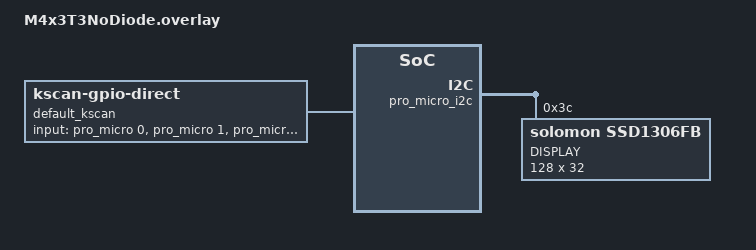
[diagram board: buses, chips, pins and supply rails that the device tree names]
#include <dt-bindings/zmk/matrix_transform.h>

/ {
	chosen {
		zmk,kscan = &default_kscan;
	};


	default_kscan: kscan {
		compatible = "zmk,kscan-gpio-direct";
		label = "default_kscan";

		diode-direction = "col2row";
		input-gpios
            = <&pro_micro 0 (GPIO_ACTIVE_HIGH | GPIO_PULL_DOWN)>
			, <&pro_micro 1 (GPIO_ACTIVE_HIGH | GPIO_PULL_DOWN)>
			, <&pro_micro 2 (GPIO_ACTIVE_HIGH | GPIO_PULL_DOWN)>
			, <&pro_micro 3 (GPIO_ACTIVE_HIGH | GPIO_PULL_DOWN)>
			, <&pro_micro 4 (GPIO_ACTIVE_HIGH | GPIO_PULL_DOWN)>
            , <&pro_micro 5 (GPIO_ACTIVE_HIGH | GPIO_PULL_DOWN)>
			, <&pro_micro 6 (GPIO_ACTIVE_HIGH | GPIO_PULL_DOWN)>
			, <&pro_micro 7 (GPIO_ACTIVE_HIGH | GPIO_PULL_DOWN)>
			, <&pro_micro 8 (GPIO_ACTIVE_HIGH | GPIO_PULL_DOWN)>
			, <&pro_micro 9 (GPIO_ACTIVE_HIGH | GPIO_PULL_DOWN)>
            , <&pro_micro 10 (GPIO_ACTIVE_HIGH | GPIO_PULL_DOWN)>
			, <&pro_micro 11 (GPIO_ACTIVE_HIGH | GPIO_PULL_DOWN)>
            , <&pro_micro 12 (GPIO_ACTIVE_HIGH | GPIO_PULL_DOWN)>
			, <&pro_micro 13 (GPIO_ACTIVE_HIGH | GPIO_PULL_DOWN)>
            , <&pro_micro 14 (GPIO_ACTIVE_HIGH | GPIO_PULL_DOWN)>
			;

	};


};

&pro_micro_i2c {
	status = "okay";

	oled: ssd1306@3c {
		compatible = "solomon,ssd1306fb";
		reg = <0x3c>;
		label = "DISPLAY";
		width = <128>;
		height = <32>;
		segment-offset = <0>;
		page-offset = <0>;
		display-offset = <0>;
		multiplex-ratio = <31>;
		segment-remap;
		com-invdir;
		com-sequential;
		prechargep = <0x22>;
	};
};
